# MINI58DE_v1 register map
File version: 1.0
Registers are 32-bit, read-write, reset 0x0 unless marked. A register's access mark holds for its fields unless they carry their own. Offsets are from the block's base; [hi:lo] are bit positions; {n}, {i} and the like mark numbered series; 'fields as' and 'values as' point back to an identical list.

## GP — GPIO Register Map
Base 0x50004000
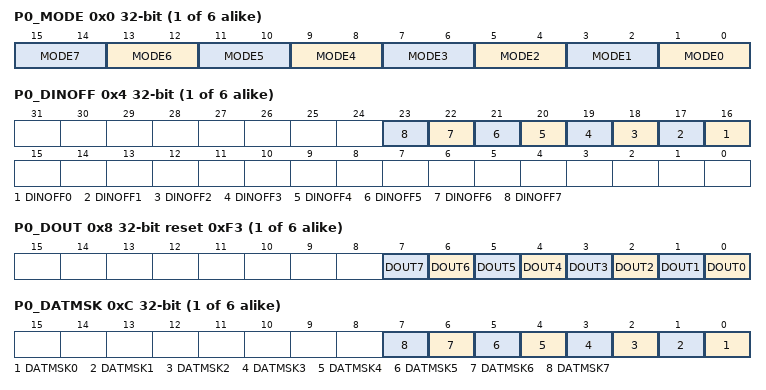
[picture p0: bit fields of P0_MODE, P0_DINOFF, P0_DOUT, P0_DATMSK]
{0x0+0x40*i} P{i}_MODE (reset mask 0xFFFF0000) (i=0..5) — P{i} I/O Mode Control
  [all] fields
    0=Px.n is in Input mode; 1=Px.n is in Push-pull Output mode; 2=Px.n is in Open-drain Output mode; 3=Px.n is in Quasi-bidirectional mode
  [2n+1:2n] MODE{n} (n=0..7) — Port 0-5 I/O Pin[N] Mode Control. Determine each I/O mode of Px.n pins.
{0x4+0x40*i} P{i}_DINOFF (i=0..5) — P{i} Digital Input Path Disable Control
  [all] fields
    0=Px.n digital input path Enabled; 1=Px.n digital input path Disabled (digital input tied to low)
  [n+16] DINOFF{n} (n=0..7) — Port 0-5 Pin[N] Digital Input Path Disable Control. Each of these bits is used to control if the digital input path of corresponding Px.n pin is disabled. If input is analog signal, users can disable Px.n digital input path to avoid input current leakage.
{0x8+0x40*i} P{i}_DOUT reset 0xF3 (i=0..5) — P{i} Data Output Value
  [all] fields
    0=Px.n will drive Low if the Px.n pin is configured as Push-pull output, Open-drain output or Quasi-bidirectional mode; 1=Px.n will drive High if the Px.n pin is configured as Push-pull output or Quasi-bidirectional mode
  [n] DOUT{n} (n=0..7) — Port 0-5 Pin[N] Output Value. Each of these bits controls the status of a Px.n pin when the Px.n is configured as Push-pull output, Open-drain output or Quasi-bidirectional mode.
{0xC+0x40*i} P{i}_DATMSK (i=0..5) — P{i} Data Output Write Mask
  [all] fields
    0=Corresponding DOUT (Px_DOUT[n]) bit can be updated; 1=Corresponding DOUT (Px_DOUT[n]) bit protected
  [n] DATMSK{n} (n=0..7) — Port 0-5 Pin[N] Data Output Write Mask. These bits are used to protect the corresponding DOUT (Px_DOUT[n]) bit. When the DATMSK (Px_DATMSK[n]) bit is set to 1, the corresponding DOUT (Px_DOUT[n]) bit is protected. If the write signal is masked, writing data to the protect bit is ignored.
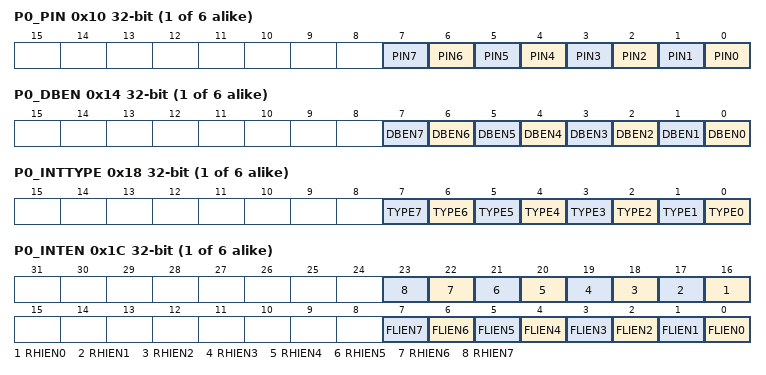
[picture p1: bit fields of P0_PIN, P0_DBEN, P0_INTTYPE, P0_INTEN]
{0x10+0x40*i} P{i}_PIN ro (reset mask 0xFFFFFF00) (i=0..5) — P{i} Pin Value
  [n] PIN{n} (n=0..7) — Port 0-5 Pin[N] Pin Value. Each bit of the register reflects the actual status of the respective Px.n pin. If the bit is 1, it indicates the corresponding pin status is high; else the pin status is low. Note:
{0x14+0x40*i} P{i}_DBEN (i=0..5) — P{i} De-bounce Enable Control
  [all] fields
    0=Px.n de-bounce function Disabled; 1=Px.n de-bounce function Enabled
  [n] DBEN{n} (n=0..7) — Port 0-5 Pin[N] Input Signal De-bounce Enable Bit. The DBEN[n] bit is used to enable the de-bounce function for each corresponding bit. If the input signal pulse width cannot be sampled by continuous two de-bounce sample cycle, the input signal transition is seen as the signal bounce and will not trigger the interrupt. The de-bounce clock source is controlled by DBCLKSRC (GPIO_DBCTL [4]), one de-bounce sample cycle period is controlled by DBCLKSEL (GPIO_DBCTL [3:0]).
{0x18+0x40*i} P{i}_INTTYPE (i=0..5) — P{i} Interrupt Mode Control
  [all] fields
    0=Edge trigger interrupt; 1=Level trigger interrupt
  [n] TYPE{n} (n=0..7) — Port 0-5 Pin[N] Edge Or Level Detection Interrupt Trigger Type Control. TYPE (Px_INTTYPE[n]) bit is used to control the triggered interrupt is by level trigger or by edge trigger. If the interrupt is by edge trigger, the trigger source can be controlled by de-bounce. If the interrupt is by level trigger, the input source is sampled by one HCLK clock and generates the interrupt.
{0x1C+0x40*i} P{i}_INTEN (i=0..5) — P{i} Interrupt Enable Control
  [n+16] RHIEN{n} (n=0..7) — Port 0-5 Pin[N] Rising Edge Or High Level Interrupt Trigger Type Enable Bit. The RHIEN (Px_INTEN[n+16]) bit is used to enable the interrupt for each of the corresponding input Px.n pin. Set bit to 1 also enable the pin wake-up function. When setting the RHIEN (Px_INTEN[n+16]) bit to 1: If the interrupt is level trigger (TYPE (Px_INTTYPE[n]) bit is set to 1), the input Px.n pin will generate the interrupt while this pin state is at high level. If the interrupt is edge trigger (TYPE (Px_INTTYPE[n]) bit is set to 0), the input Px.n pin will generate the interrupt while this pin state changed from low to high.
    0=Px.n level high or low to high interrupt Disabled; 1=Px.n level high or low to high interrupt Enabled
  [n] FLIEN{n} (n=0..7) — Port 0-5 Pin[N] Falling Edge Or Low Level Interrupt Trigger Type Enable Bit. The FLIEN (Px_INTEN[n]) bit is used to enable the interrupt for each of the corresponding input Px.n pin. Set bit to 1 also enable the pin wake-up function. When setting the FLIEN (Px_INTEN[n]) bit to 1: If the interrupt is level trigger (TYPE (Px_INTTYPE[n]) bit is set to 1), the input Px.n pin will generate the interrupt while this pin state is at low level. If the interrupt is edge trigger (TYPE (Px_INTTYPE[n]) bit is set to 0), the input Px.n pin will generate the interrupt while this pin state changed from high to low.
    0=Px.n level low or high to low interrupt Disabled; 1=Px.n level low or high to low interrupt Enabled
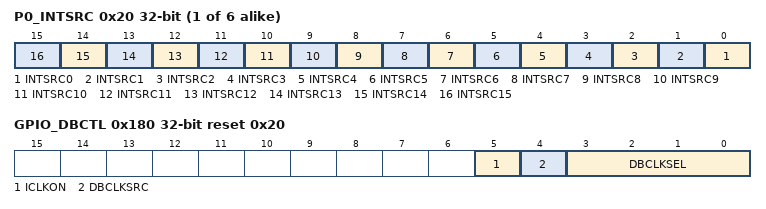
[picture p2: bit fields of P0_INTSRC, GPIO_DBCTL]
{0x20+0x40*i} P{i}_INTSRC (i=0..5) — P{i} Interrupt Source Flag
  [all] fields
    0=No action. No interrupt at Px.n; 1=Clear the corresponding pending interrupt. Px.n generates an interrupt
  [n] INTSRC{n} (n=0..15) — Port 0-5 Pin[N] Interrupt Source Flag. Write Operation:
0x180 GPIO_DBCTL reset 0x20 — De-bounce Cycle Control
  [5] ICLKON — Interrupt Clock On Mode. Note: It is recommended to disable this bit to save system power if no special application concern.
    0=Edge detection circuit is active only if I/O pin corresponding RHIEN (Px_INTEN[n+16])/FLIEN (Px_INTEN[n]) bit is set to 1; 1=All I/O pins edge detection circuit is always active after reset
  [4] DBCLKSRC — De-bounce Counter Clock Source Selection
    0=De-bounce counter clock source is HCLK; 1=De-bounce counter clock source is 10 kHz internal low speed RC oscillator (LIRC)
  [3:0] DBCLKSEL — De-bounce Sampling Cycle Selection
    0=Sample interrupt input once per 1 clock; 1=Sample interrupt input once per 2 clocks; 2=Sample interrupt input once per 4 clocks; 3=Sample interrupt input once per 8 clocks; 4=Sample interrupt input once per 16 clocks; 5=Sample interrupt input once per 32 clocks; 6=Sample interrupt input once per 64 clocks; 7=Sample interrupt input once per 128 clocks; 8=Sample interrupt input once per 256 clocks; 9=Sample interrupt input once per 2*256 clocks; 10=Sample interrupt input once per 4*256 clocks; 11=Sample interrupt input once per 8*256 clocks; 12=Sample interrupt input once per 16*256 clocks; 13=Sample interrupt input once per 32*256 clocks; 14=Sample interrupt input once per 64*256 clocks; 15=Sample interrupt input once per 128*256 clocks
0x200 P00_PDIO reset 0x1 — GPIO P0.0 Pin Data Input/Output
  [0] PDIO — GPIO Px.N Pin Data Input/Output. Writing this bit can control one GPIO pin output value.
    0=Corresponding GPIO pin set to low; 1=Corresponding GPIO pin set to high
0x204 P01_PDIO reset 0x1 — GPIO P0.1 Pin Data Input/Output
  fields as P00_PDIO
0x210 P04_PDIO reset 0x1 — GPIO P0.4 Pin Data Input/Output
  fields as P00_PDIO
0x214 P05_PDIO reset 0x1 — GPIO P0.5 Pin Data Input/Output
  fields as P00_PDIO
0x218 P06_PDIO reset 0x1 — GPIO P0.6 Pin Data Input/Output
  fields as P00_PDIO
0x21C P07_PDIO reset 0x1 — GPIO P0.7 Pin Data Input/Output
  fields as P00_PDIO
0x220 P10_PDIO reset 0x1 — GPIO P1.0 Pin Data Input/Output
  fields as P00_PDIO
0x228 P12_PDIO reset 0x1 — GPIO P1.2 Pin Data Input/Output
  fields as P00_PDIO
0x22C P13_PDIO reset 0x1 — GPIO P1.3 Pin Data Input/Output
  fields as P00_PDIO
0x230 P14_PDIO reset 0x1 — GPIO P1.4 Pin Data Input/Output
  fields as P00_PDIO
0x234 P15_PDIO reset 0x1 — GPIO P1.5 Pin Data Input/Output
  fields as P00_PDIO
0x248 P22_PDIO reset 0x1 — GPIO P2.2 Pin Data Input/Output
  fields as P00_PDIO
0x24C P23_PDIO reset 0x1 — GPIO P2.3 Pin Data Input/Output
  fields as P00_PDIO
0x250 P24_PDIO reset 0x1 — GPIO P2.4 Pin Data Input/Output
  fields as P00_PDIO
0x254 P25_PDIO reset 0x1 — GPIO P2.5 Pin Data Input/Output
  fields as P00_PDIO
0x258 P26_PDIO reset 0x1 — GPIO P2.6 Pin Data Input/Output
  fields as P00_PDIO
0x260 P30_PDIO reset 0x1 — GPIO P3.0 Pin Data Input/Output
  fields as P00_PDIO
0x264 P31_PDIO reset 0x1 — GPIO P3.1 Pin Data Input/Output
  fields as P00_PDIO
0x268 P32_PDIO reset 0x1 — GPIO P3.2 Pin Data Input/Output
  fields as P00_PDIO
0x270 P34_PDIO reset 0x1 — GPIO P3.4 Pin Data Input/Output
  fields as P00_PDIO
0x274 P35_PDIO reset 0x1 — GPIO P3.5 Pin Data Input/Output
  fields as P00_PDIO
0x278 P36_PDIO reset 0x1 — GPIO P3.6 Pin Data Input/Output
  fields as P00_PDIO
0x298 P46_PDIO reset 0x1 — GPIO P4.6 Pin Data Input/Output
  fields as P00_PDIO
0x29C P47_PDIO reset 0x1 — GPIO P4.7 Pin Data Input/Output
  fields as P00_PDIO
0x2A0 P50_PDIO reset 0x1 — GPIO P5.0 Pin Data Input/Output
  fields as P00_PDIO
0x2A4 P51_PDIO reset 0x1 — GPIO P5.1 Pin Data Input/Output
  fields as P00_PDIO
0x2A8 P52_PDIO reset 0x1 — GPIO P5.2 Pin Data Input/Output
  fields as P00_PDIO
0x2AC P53_PDIO reset 0x1 — GPIO P5.3 Pin Data Input/Output
  fields as P00_PDIO
0x2B0 P54_PDIO reset 0x1 — GPIO P5.4 Pin Data Input/Output
  fields as P00_PDIO
0x2B4 P55_PDIO reset 0x1 — GPIO P5.5 Pin Data Input/Output
  fields as P00_PDIO
